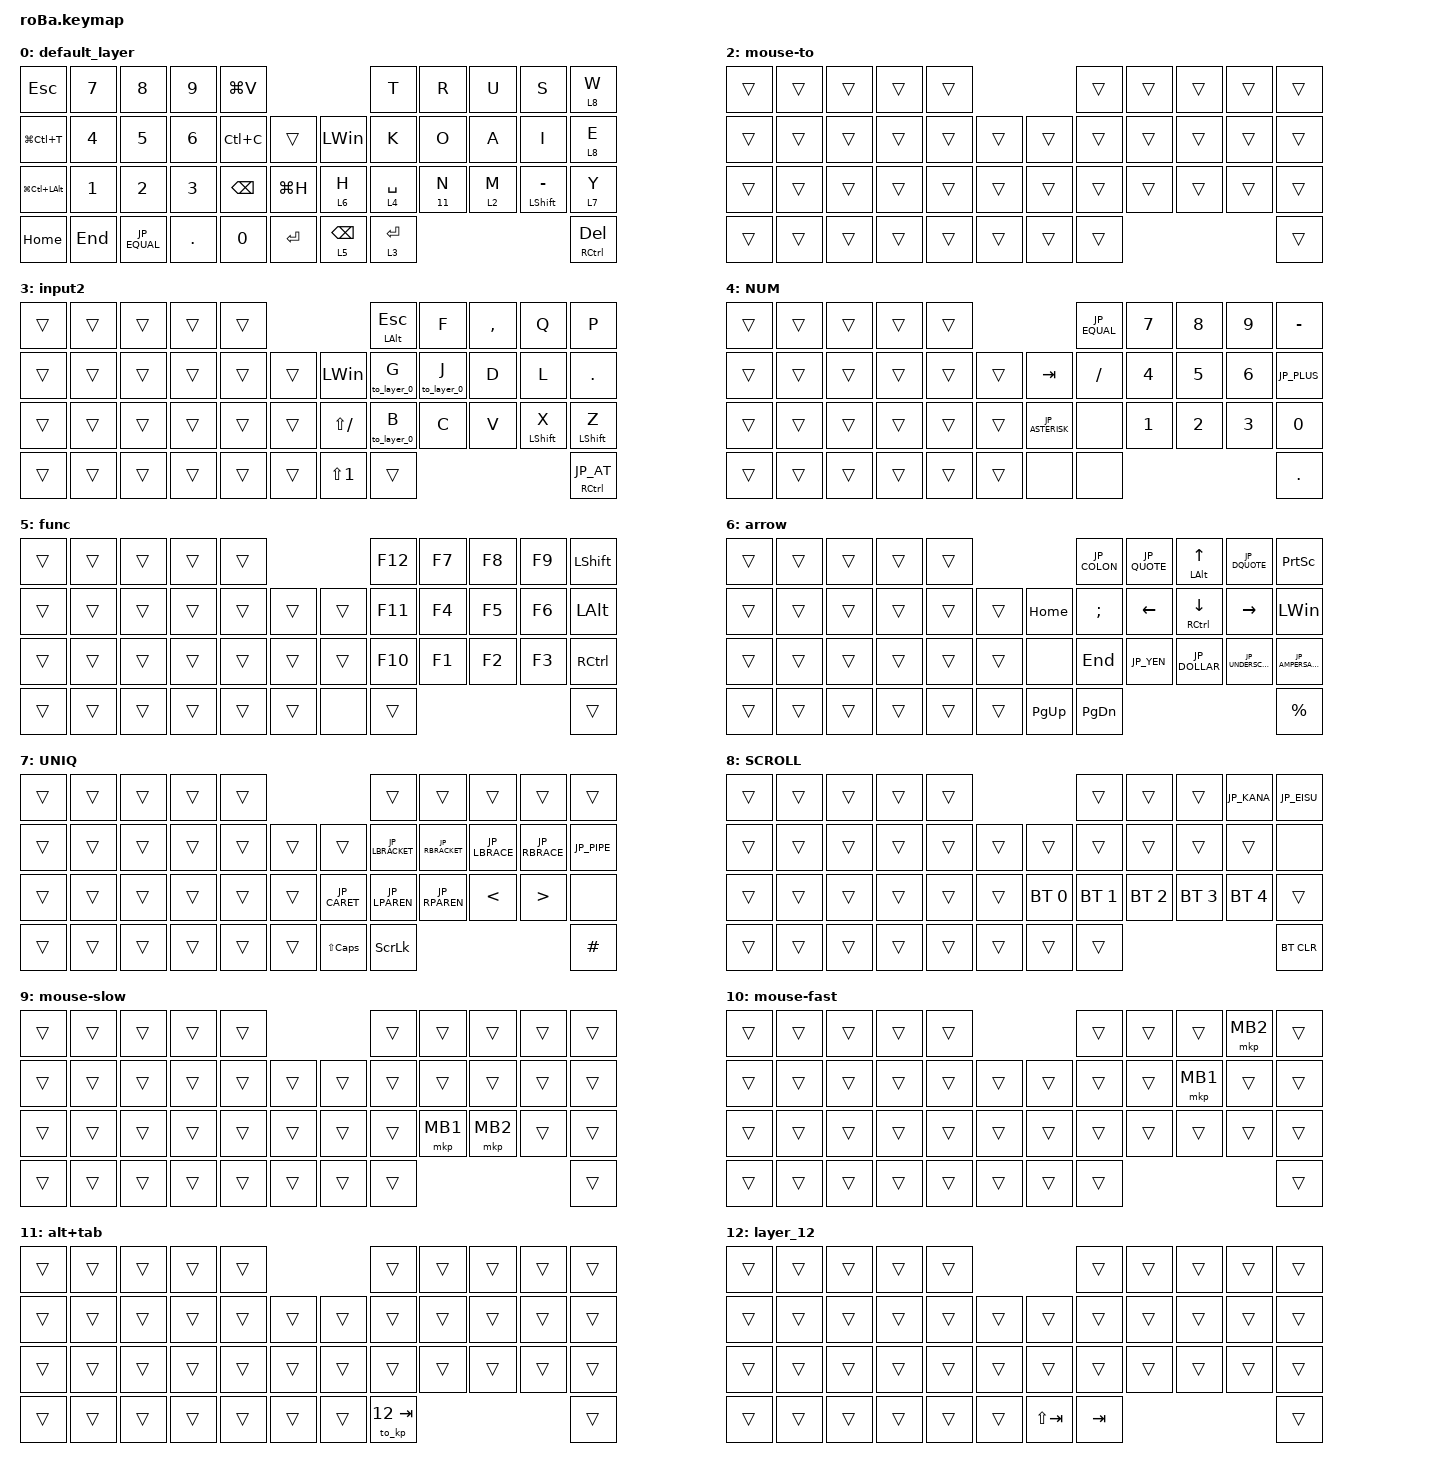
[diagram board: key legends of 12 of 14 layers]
#include <input/processors.dtsi>
#include <behaviors.dtsi>
#include <dt-bindings/zmk/bt.h>
#include <dt-bindings/zmk/keys.h>
#include <dt-bindings/zmk/pointing.h>

// OS設定を日本語キーボードのまま使用するための変換定義

#define JP_DQUOTE       AT                // "
#define JP_AMPERSAND    CARET             // &
#define JP_QUOTE        AMPERSAND         // '
#define JP_EQUAL        UNDER             // =
#define JP_CARET        EQUAL             // ^
#define JP_YEN          0x89              // ¥
#define JP_PLUS         COLON             // +
#define JP_TILDE        PLUS              // ~
#define JP_PIPE         LS(0x89)          // |
#define JP_AT           LEFT_BRACKET      // @
#define JP_COLON        SINGLE_QUOTE      // :
#define JP_ASTERISK     DOUBLE_QUOTES     // *
#define JP_BACKQUOTE    LEFT_BRACE        // `
#define JP_UNDERSCORE   LS(0x87)          // _
#define JP_LBRACKET     RIGHT_BRACKET     // [
#define JP_RBRACKET     BACKSLASH         // ]
#define JP_LPAREN       ASTERISK          // (
#define JP_RPAREN       LEFT_PARENTHESIS  // )
#define JP_LBRACE       RIGHT_BRACE       // {
#define JP_RBRACE       PIPE              // }
#define JP_KANA         LANGUAGE_1        // かな
#define JP_EISU         LANGUAGE_2        // 英数
#define JP_HANZEN       GRAVE             // 半角/全角
#define JP_DOLLAR       DOLLAR            // $

// クリックでtemp_layer延長

&mkp_input_listener { input-processors = <&zip_temp_layer 1 380>; };

&mt {
    flavor = "balanced";
    quick-tap-ms = <300>;
};

&lt {
    quick-tap-ms = <300>;
    flavor = "balanced";
};

/ {
    layer_listeners {
        compatible = "zmk,layer-listeners";

        release_alt {
            layers = <12>;
            bindings = <&kt_on LEFT_ALT &kt_off LEFT_ALT>;
        };
    };

    combos {
        compatible = "zmk,combos";

        snipe {
            bindings = <&mo 9>;
            key-positions = <32 33>;
        };
    };

    macros {
        to_layer_0: to_layer_0 {
            compatible = "zmk,behavior-macro-one-param";
            #binding-cells = <1>;
            bindings = <&to 0 &macro_param_1to1 &kp MACRO_PLACEHOLDER>;
            label = "TO_LAYER_0";
        };

        to_kp: to_kp {
            compatible = "zmk,behavior-macro-two-param";
            #binding-cells = <2>;
            bindings = <&macro_param_1to1 &to MACRO_PLACEHOLDER &macro_param_2to1 &kp MACRO_PLACEHOLDER>;
            label = "to_kp";
        };

        mo_to_0: mo_to_0 {
            compatible = "zmk,behavior-macro-one-param";
            wait-ms = <0>;
            tap-ms = <0>;
            #binding-cells = <1>;
            bindings =
                <&macro_press>,
                <&macro_param_1to1 &mo MACRO_PLACEHOLDER>,
                <&macro_tap>,
                <&macro_pause_for_release>,
                <&macro_release>,
                <&macro_param_1to1 &mo MACRO_PLACEHOLDER>,
                <&macro_tap>,
                <&to 0>;

            label = "MO_to_0";
        };

        exit_AML: exit_AML {
            compatible = "zmk,behavior-macro";
            wait-ms = <0>;
            tap-ms = <0>;
            #binding-cells = <0>;
            bindings = <&tog_off 1>;
            label = "exit_AML";
        };

        /omit-if-no-ref/

        eager_tap_dance: eager_tap_dance {
            compatible = "zmk,behavior-macro-two-param";
            #binding-cells = <2>;
            bindings =
                <&macro_press>,
                <&macro_param_1to1 &kp MACRO_PLACEHOLDER>,
                <&macro_pause_for_release>,
                <&macro_release>,
                <&macro_param_1to1 &kp MACRO_PLACEHOLDER>,
                <&macro_tap>,
                <&exit_AML &macro_param_2to1 &sl_250 MACRO_PLACEHOLDER>;
        };

        kp_exit_AML: kp_exit_AML {
            compatible = "zmk,behavior-macro-one-param";
            wait-ms = <0>;
            tap-ms = <0>;
            #binding-cells = <1>;
            bindings = <&macro_param_1to1 &kp MACRO_PLACEHOLDER &exit_AML>;
            label = "KP_exit_AML";
        };
    };

    behaviors {
        kt_on: key_toggle_on_only {
            compatible = "zmk,behavior-key-toggle";
            #binding-cells = <1>;
            display-name = "Key Toggle On";
            toggle-mode = "on";
        };

        kt_off: key_toggle_off_only {
            compatible = "zmk,behavior-key-toggle";
            #binding-cells = <1>;
            display-name = "Key Toggle Off";
            toggle-mode = "off";
        };

        lt_to_0: lt_to_0 {
            compatible = "zmk,behavior-hold-tap";
            label = "LT_to_0";
            bindings = <&mo_to_0>, <&kp>;

            #binding-cells = <2>;
            tapping-term-ms = <200>;
            quick-tap-ms = <200>;
            flavor = "balanced";
        };

        tog_on: toggle_layer_on_only {
            compatible = "zmk,behavior-toggle-layer";
            #binding-cells = <1>;
            display-name = "Toggle Layer On";
            toggle-mode = "on";
        };

        tog_off: toggle_layer_off_only {
            compatible = "zmk,behavior-toggle-layer";
            #binding-cells = <1>;
            display-name = "Toggle Layer Off";
            toggle-mode = "off";
        };

        mt_exit_AML_on_tap: mt_exit_AML_on_tap {
            compatible = "zmk,behavior-hold-tap";
            label = "MT_exit_AML_ON_TAP";
            bindings = <&kp>, <&kp_exit_AML>;

            #binding-cells = <2>;
            tapping-term-ms = <200>;
            flavor = "balanced";
            quick-tap-ms = <200>;
        };

        /omit-if-no-ref/

        sl_250: sl_250 {
            compatible = "zmk,behavior-sticky-key";
            bindings = <&mo>;
            #binding-cells = <1>;
            release-after-ms = <250>;
        };
    };

    keymap {
        compatible = "zmk,keymap";

        default_layer {
            bindings = <
&kp ESCAPE            &kp NUMBER_7  &kp NUMBER_8  &kp NUMBER_9  &kp LG(V)                                      &kp T        &kp R          &kp U    &kp S                 &lt 8 W
&kp LG(LC(T))         &kp NUMBER_4  &kp NUMBER_5  &kp NUMBER_6  &kp LC(C)      &trans         &kp LEFT_WIN     &kp K        &kp O          &kp A    &kp I                 &lt 8 E
&kp LG(LC(LEFT_ALT))  &kp NUMBER_1  &kp NUMBER_2  &kp NUMBER_3  &kp BACKSPACE  &kp LG(H)      &lt 6 H          &lt 4 SPACE  &lt_to_0 11 N  &lt 2 M  &mt LEFT_SHIFT MINUS  &lt 7 Y
&kp HOME              &kp END       &kp JP_EQUAL  &kp DOT       &kp NUMBER_0   &kp ENTER      &lt 5 BACKSPACE  &lt 3 ENTER                                                &mt RCTRL DEL
            >;

            sensor-bindings = <&inc_dec_kp LC(PAGE_UP) LC(PAGE_DOWN)>;
        };

        MOUSE {
            bindings = <
&trans  &trans  &trans  &trans  &trans                      &trans  &trans  &trans    &mkp MB2                              &lt_to_0 (8) LC(C)
&trans  &trans  &trans  &trans  &trans  &trans      &trans  &trans  &trans  &mkp MB1  &trans                                &kp LC(V)
&trans  &trans  &trans  &trans  &trans  &trans      &trans  &trans  &trans  &trans    &mt_exit_AML_on_tap LEFT_SHIFT MINUS  &trans
&trans  &trans  &trans  &trans  &trans  &trans      &trans  &trans                                                          &trans
            >;
        };

        mouse-to {
            bindings = <
&trans  &trans  &trans  &trans  &trans                      &trans  &trans  &trans  &trans  &trans
&trans  &trans  &trans  &trans  &trans  &trans      &trans  &trans  &trans  &trans  &trans  &trans
&trans  &trans  &trans  &trans  &trans  &trans      &trans  &trans  &trans  &trans  &trans  &trans
&trans  &trans  &trans  &trans  &trans  &trans      &trans  &trans                          &trans
            >;
        };

        input2 {
            bindings = <
&trans  &trans  &trans  &trans  &trans                                &mt LEFT_ALT ESCAPE  &kp F          &kp COMMA  &kp Q             &kp P
&trans  &trans  &trans  &trans  &trans  &trans      &kp LEFT_WIN      &to_layer_0 G        &to_layer_0 J  &kp D      &kp L             &kp PERIOD
&trans  &trans  &trans  &trans  &trans  &trans      &kp LS(SLASH)     &to_layer_0 B        &kp C          &kp V      &mt LEFT_SHIFT X  &mt LEFT_SHIFT Z
&trans  &trans  &trans  &trans  &trans  &trans      &kp LS(NUMBER_1)  &trans                                                           &mt RCTRL JP_AT
            >;
        };

        NUM {
            bindings = <
&trans  &trans  &trans  &trans  &trans                               &kp JP_EQUAL  &kp N7        &kp N8        &kp N9        &kp MINUS
&trans  &trans  &trans  &trans  &trans  &trans      &kp TAB          &kp SLASH     &kp NUMBER_4  &kp N5        &kp NUMBER_6  &kp JP_PLUS
&trans  &trans  &trans  &trans  &trans  &trans      &kp JP_ASTERISK  &none         &kp NUMBER_1  &kp NUMBER_2  &kp NUMBER_3  &kp N0
&trans  &trans  &trans  &trans  &trans  &trans      &none            &none                                                   &kp PERIOD
            >;
        };

        func {
            bindings = <
&trans  &trans  &trans  &trans  &trans                      &kp F12  &kp F7  &kp F8  &kp F9  &kp LEFT_SHIFT
&trans  &trans  &trans  &trans  &trans  &trans      &trans  &kp F11  &kp F4  &kp F5  &kp F6  &kp LEFT_ALT
&trans  &trans  &trans  &trans  &trans  &trans      &trans  &kp F10  &kp F1  &kp F2  &kp F3  &kp RCTRL
&trans  &trans  &trans  &trans  &trans  &trans      &none   &trans                           &trans
            >;
        };

        arrow {
            bindings = <
&trans  &trans  &trans  &trans  &trans                           &kp JP_COLON   &kp JP_QUOTE    &mt LEFT_ALT UP_ARROW  &kp JP_DQUOTE      &kp PSCRN
&trans  &trans  &trans  &trans  &trans  &trans      &kp HOME     &kp SEMI       &kp LEFT_ARROW  &mt RCTRL DOWN_ARROW   &kp RIGHT_ARROW    &kp LEFT_WIN
&trans  &trans  &trans  &trans  &trans  &trans      &none        &kp END        &kp JP_YEN      &kp JP_DOLLAR          &kp JP_UNDERSCORE  &kp JP_AMPERSAND
&trans  &trans  &trans  &trans  &trans  &trans      &kp PAGE_UP  &kp PAGE_DOWN                                                            &kp PERCENT
            >;
        };

        UNIQ {
            bindings = <
&trans  &trans  &trans  &trans  &trans                            &trans           &trans           &trans         &trans         &trans
&trans  &trans  &trans  &trans  &trans  &trans      &trans        &kp JP_LBRACKET  &kp JP_RBRACKET  &kp JP_LBRACE  &kp JP_RBRACE  &kp JP_PIPE
&trans  &trans  &trans  &trans  &trans  &trans      &kp JP_CARET  &kp JP_LPAREN    &kp JP_RPAREN    &kp LT         &kp GT         &none
&trans  &trans  &trans  &trans  &trans  &trans      &kp LS(CLCK)  &kp SCROLLLOCK                                                  &kp HASH
            >;
        };

        SCROLL {
            bindings = <
&trans  &trans  &trans  &trans  &trans                            &trans        &trans        &trans        &kp JP_KANA   &kp JP_EISU
&trans  &trans  &trans  &trans  &trans  &trans      &trans        &trans        &trans        &trans        &trans        &none
&trans  &trans  &trans  &trans  &trans  &trans      &bt BT_SEL 0  &bt BT_SEL 1  &bt BT_SEL 2  &bt BT_SEL 3  &bt BT_SEL 4  &trans
&trans  &trans  &trans  &trans  &trans  &trans      &trans        &trans                                                  &bt BT_CLR
            >;
        };

        mouse-slow {
            bindings = <
&trans  &trans  &trans  &trans  &trans                      &trans  &trans    &trans    &trans  &trans
&trans  &trans  &trans  &trans  &trans  &trans      &trans  &trans  &trans    &trans    &trans  &trans
&trans  &trans  &trans  &trans  &trans  &trans      &trans  &trans  &mkp MB1  &mkp MB2  &trans  &trans
&trans  &trans  &trans  &trans  &trans  &trans      &trans  &trans                              &trans
            >;
        };

        mouse-fast {
            bindings = <
&trans  &trans  &trans  &trans  &trans                      &trans  &trans  &trans    &mkp MB2  &trans
&trans  &trans  &trans  &trans  &trans  &trans      &trans  &trans  &trans  &mkp MB1  &trans    &trans
&trans  &trans  &trans  &trans  &trans  &trans      &trans  &trans  &trans  &trans    &trans    &trans
&trans  &trans  &trans  &trans  &trans  &trans      &trans  &trans                              &trans
            >;
        };

        alt+tab {
            bindings = <
&trans  &trans  &trans  &trans  &trans                      &trans         &trans  &trans  &trans  &trans
&trans  &trans  &trans  &trans  &trans  &trans      &trans  &trans         &trans  &trans  &trans  &trans
&trans  &trans  &trans  &trans  &trans  &trans      &trans  &trans         &trans  &trans  &trans  &trans
&trans  &trans  &trans  &trans  &trans  &trans      &trans  &to_kp 12 TAB                          &trans
            >;
        };

        layer_12 {
            bindings = <
&trans  &trans  &trans  &trans  &trans                           &trans   &trans  &trans  &trans  &trans
&trans  &trans  &trans  &trans  &trans  &trans      &trans       &trans   &trans  &trans  &trans  &trans
&trans  &trans  &trans  &trans  &trans  &trans      &trans       &trans   &trans  &trans  &trans  &trans
&trans  &trans  &trans  &trans  &trans  &trans      &kp LS(TAB)  &kp TAB                          &trans
            >;
        };

        layer_13 {
            bindings = <
&trans  &trans  &trans  &trans  &trans                      &trans  &trans  &trans  &trans  &trans
&trans  &trans  &trans  &trans  &trans  &trans      &trans  &trans  &trans  &trans  &trans  &trans
&trans  &trans  &trans  &trans  &trans  &trans      &trans  &trans  &trans  &trans  &trans  &trans
&trans  &trans  &trans  &trans  &trans  &trans      &trans  &trans                          &trans
            >;
        };
    };
};
